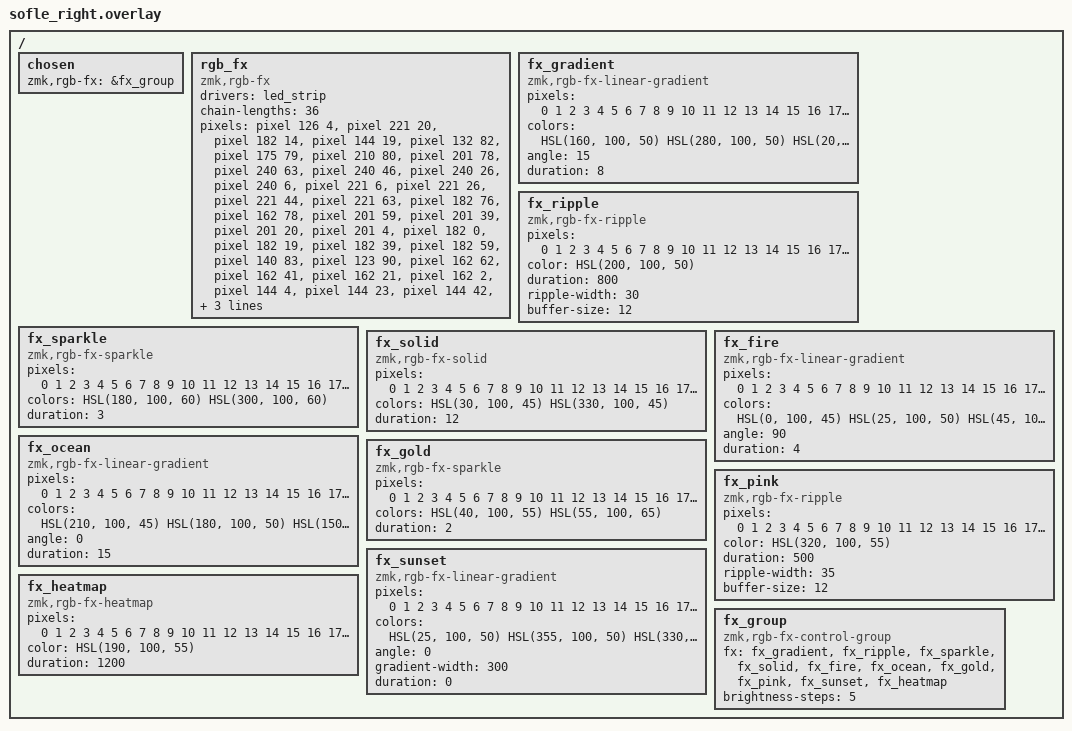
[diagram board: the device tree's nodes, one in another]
/*
 * RGB FX - right half (Sofle MX, 36 LEDs).
 *
 * Mirror of sofle_left.overlay across the continuous canvas (right half
 * x 123 = inner edge, x 240 = outer/pinky) so horizontal gradients cross
 * the seam without a jump.
 * Chain order: LED 1 = encoder indicator, 2-7 = underglow, 8-36 = per-key.
 * Like the left half, x was flipped (x' = 363 - x) after confirming on
 * hardware that the original photo-derived map was mirrored.
 */

#include <rgb_fx.dtsi>
#include <dt-bindings/zmk/rgb_fx.h>

/ {
    chosen {
        zmk,rgb-fx = &fx_group;
    };

    rgb_fx: rgb_fx {
        compatible = "zmk,rgb-fx";
        drivers = <&led_strip>;
        chain-lengths = <36>;
        pixels
            = <&pixel 126 4>, /*  0 = LED#1 encoder indicator (inner) */
              <&pixel 221 20>, /*  1 = LED#2 underglow 1 */
              <&pixel 182 14>, /*  2 = LED#3 underglow 2 */
              <&pixel 144 19>, /*  3 = LED#4 underglow 3 */
              <&pixel 132 82>, /*  4 = LED#5 underglow 4 */
              <&pixel 175 79>, /*  5 = LED#6 underglow 5 */
              <&pixel 210 80>, /*  6 = LED#7 underglow 6 */
              <&pixel 201 78>, /*  7 = LED#8 thumb GUI (outermost) */
              <&pixel 240 63>, /*  8 = LED#9 pinky col row3 */
              <&pixel 240 46>, /*  9 = LED#10 pinky col row2 */
              <&pixel 240 26>, /* 10 = LED#11 pinky col row1 */
              <&pixel 240 6>, /* 11 = LED#12 pinky col row0 */
              <&pixel 221 6>, /* 12 = LED#13 col1 row0 */
              <&pixel 221 26>, /* 13 = LED#14 col1 row1 */
              <&pixel 221 44>, /* 14 = LED#15 col1 row2 */
              <&pixel 221 63>, /* 15 = LED#16 col1 row3 */
              <&pixel 182 76>, /* 16 = LED#17 thumb ALT */
              <&pixel 162 78>, /* 17 = LED#18 thumb CTRL */
              <&pixel 201 59>, /* 18 = LED#19 col2 row3 */
              <&pixel 201 39>, /* 19 = LED#20 col2 row2 */
              <&pixel 201 20>, /* 20 = LED#21 col2 row1 */
              <&pixel 201 4>, /* 21 = LED#22 col2 row0 */
              <&pixel 182 0>, /* 22 = LED#23 col3 row0 */
              <&pixel 182 19>, /* 23 = LED#24 col3 row1 */
              <&pixel 182 39>, /* 24 = LED#25 col3 row2 */
              <&pixel 182 59>, /* 25 = LED#26 col3 row3 */
              <&pixel 140 83>, /* 26 = LED#27 thumb RAISE */
              <&pixel 123 90>, /* 27 = LED#28 thumb SPACE (innermost) */
              <&pixel 162 62>, /* 28 = LED#29 col4 row3 */
              <&pixel 162 41>, /* 29 = LED#30 col4 row2 */
              <&pixel 162 21>, /* 30 = LED#31 col4 row1 */
              <&pixel 162 2>, /* 31 = LED#32 col4 row0 */
              <&pixel 144 4>, /* 32 = LED#33 inner col row0 */
              <&pixel 144 23>, /* 33 = LED#34 inner col row1 */
              <&pixel 144 42>, /* 34 = LED#35 inner col row2 */
              <&pixel 144 62>; /* 35 = LED#36 inner col row3 */
        key-pixels
            = <32 32 32 32 32 32 32 31 22 21 12 11
               33 33 33 33 33 33 33 30 23 20 13 10
               34 34 34 34 34 34 34 29 24 19 14  9
               35 35 35 35 35 35 35  0 35 28 25 18 15  8
               27 27 27 27 27 27 26 17 16  7>;
    };

    fx_gradient: fx_gradient {
        compatible = "zmk,rgb-fx-linear-gradient";
        pixels = <0 1 2 3 4 5 6 7 8 9 10 11 12 13 14 15 16 17 18 19 20 21 22 23 24 25 26 27 28 29 30 31 32 33 34 35>;
        colors = <HSL(160, 100, 50) HSL(280, 100, 50) HSL(20, 100, 50)>;
        angle = <15>;
        duration = <8>;
    };

    fx_ripple: fx_ripple {
        compatible = "zmk,rgb-fx-ripple";
        pixels = <0 1 2 3 4 5 6 7 8 9 10 11 12 13 14 15 16 17 18 19 20 21 22 23 24 25 26 27 28 29 30 31 32 33 34 35>;
        color = <HSL(200, 100, 50)>;
        duration = <800>;
        ripple-width = <30>;
        buffer-size = <12>;
    };

    fx_sparkle: fx_sparkle {
        compatible = "zmk,rgb-fx-sparkle";
        pixels = <0 1 2 3 4 5 6 7 8 9 10 11 12 13 14 15 16 17 18 19 20 21 22 23 24 25 26 27 28 29 30 31 32 33 34 35>;
        colors = <HSL(180, 100, 60) HSL(300, 100, 60)>;
        duration = <3>;
    };

    fx_solid: fx_solid {
        compatible = "zmk,rgb-fx-solid";
        pixels = <0 1 2 3 4 5 6 7 8 9 10 11 12 13 14 15 16 17 18 19 20 21 22 23 24 25 26 27 28 29 30 31 32 33 34 35>;
        colors = <HSL(30, 100, 45) HSL(330, 100, 45)>;
        duration = <12>;
    };


    fx_fire: fx_fire {
        compatible = "zmk,rgb-fx-linear-gradient";
        pixels = <0 1 2 3 4 5 6 7 8 9 10 11 12 13 14 15 16 17 18 19 20 21 22 23 24 25 26 27 28 29 30 31 32 33 34 35>;
        colors = <HSL(0, 100, 45) HSL(25, 100, 50) HSL(45, 100, 55)>;
        angle = <90>;
        duration = <4>;
    };

    fx_ocean: fx_ocean {
        compatible = "zmk,rgb-fx-linear-gradient";
        pixels = <0 1 2 3 4 5 6 7 8 9 10 11 12 13 14 15 16 17 18 19 20 21 22 23 24 25 26 27 28 29 30 31 32 33 34 35>;
        colors = <HSL(210, 100, 45) HSL(180, 100, 50) HSL(150, 90, 45)>;
        angle = <0>;
        duration = <15>;
    };

    fx_gold: fx_gold {
        compatible = "zmk,rgb-fx-sparkle";
        pixels = <0 1 2 3 4 5 6 7 8 9 10 11 12 13 14 15 16 17 18 19 20 21 22 23 24 25 26 27 28 29 30 31 32 33 34 35>;
        colors = <HSL(40, 100, 55) HSL(55, 100, 65)>;
        duration = <2>;
    };

    fx_pink: fx_pink {
        compatible = "zmk,rgb-fx-ripple";
        pixels = <0 1 2 3 4 5 6 7 8 9 10 11 12 13 14 15 16 17 18 19 20 21 22 23 24 25 26 27 28 29 30 31 32 33 34 35>;
        color = <HSL(320, 100, 55)>;
        duration = <500>;
        ripple-width = <35>;
        buffer-size = <12>;
    };

    fx_sunset: fx_sunset {
        compatible = "zmk,rgb-fx-linear-gradient";
        pixels = <0 1 2 3 4 5 6 7 8 9 10 11 12 13 14 15 16 17 18 19 20 21 22 23 24 25 26 27 28 29 30 31 32 33 34 35>;
        colors = <HSL(25, 100, 50) HSL(355, 100, 50) HSL(330, 100, 50)
                  HSL(285, 100, 50) HSL(235, 100, 50)>;
        angle = <0>;
        gradient-width = <300>;
        duration = <0>;
    };

    fx_heatmap: fx_heatmap {
        compatible = "zmk,rgb-fx-heatmap";
        pixels = <0 1 2 3 4 5 6 7 8 9 10 11 12 13 14 15 16 17 18 19 20 21 22 23 24 25 26 27 28 29 30 31 32 33 34 35>;
        color = <HSL(190, 100, 55)>;
        duration = <1200>;
    };

    fx_group: fx_group {
        compatible = "zmk,rgb-fx-control-group";
        fx = <&fx_gradient &fx_ripple &fx_sparkle &fx_solid
              &fx_fire &fx_ocean &fx_gold &fx_pink &fx_sunset &fx_heatmap>;
        brightness-steps = <5>;
    };
};
